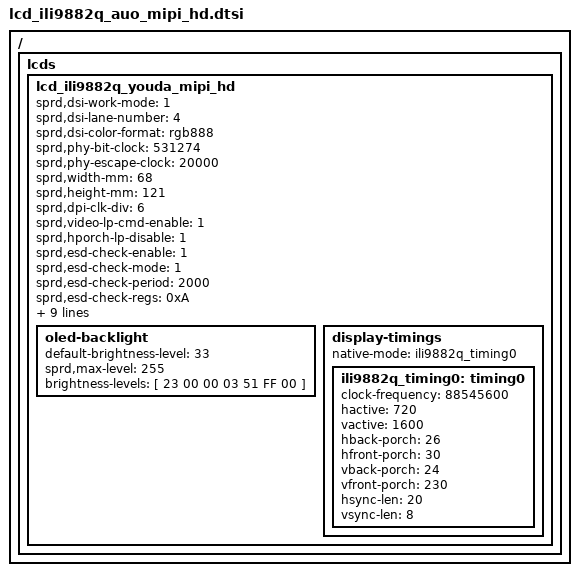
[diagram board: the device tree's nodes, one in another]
/ {
	fragment {
		target-path = "/";
		__overlay__ {
			lcds {
				lcd_ili9882q_youda_mipi_hd: lcd_ili9882q_youda_mipi_hd {

				sprd,dsi-work-mode = <1>; /* video burst mode*/
				sprd,dsi-lane-number = <4>;
				sprd,dsi-color-format = "rgb888";

				sprd,phy-bit-clock = <531274>;	/* kbps */
				sprd,phy-escape-clock = <20000>;/* kHz */
				sprd,width-mm = <68>;
				sprd,height-mm = <121>;
				sprd,dpi-clk-div = <6>;
				sprd,video-lp-cmd-enable = <1>;
				sprd,hporch-lp-disable = <1>;

				sprd,esd-check-enable = <1>;
				sprd,esd-check-mode = <1>;
				sprd,esd-check-period = <2000>;
				sprd,esd-check-regs = <0xA>;
				sprd,esd-return-code = <0x9C>;

				sprd,reset-on-sequence = <1 5>, <0 5>, <1 20>;
				sprd,reset-off-sequence = <1 5>;

				sprd,initial-command = [
					39 00 00 04 FF 98 82 06
					23 00 00 02 3E 60
					39 00 00 04 FF 98 82 01
					23 00 00 02 00 4C
					23 00 00 02 01 25
					23 00 00 02 02 00
					23 00 00 02 03 00
					23 00 00 02 04 03
					23 00 00 02 05 25
					23 00 00 02 06 00
					23 00 00 02 07 00
					23 00 00 02 08 84
					23 00 00 02 09 85
					23 00 00 02 0A F5
					23 00 00 02 0B 00
					23 00 00 02 0C 07
					23 00 00 02 0D 07
					23 00 00 02 0E 00
					23 00 00 02 0F 00
					23 00 00 02 10 00
					23 00 00 02 11 00
					23 00 00 02 12 00
					23 00 00 02 14 87
					23 00 00 02 15 87
					23 00 00 02 16 84
					23 00 00 02 17 85
					23 00 00 02 18 75
					23 00 00 02 19 00
					23 00 00 02 1A 06
					23 00 00 02 1B 06
					23 00 00 02 1C 00
					23 00 00 02 1D 00
					23 00 00 02 1E 00
					23 00 00 02 1F 00
					23 00 00 02 20 00
					23 00 00 02 22 87
					23 00 00 02 23 87
					23 00 00 02 2A 8B
					23 00 00 02 2B 4E
					23 00 00 02 31 2A
					23 00 00 02 32 2A
					23 00 00 02 33 0C
					23 00 00 02 34 0C
					23 00 00 02 35 23
					23 00 00 02 36 23
					23 00 00 02 37 2A
					23 00 00 02 38 2A
					23 00 00 02 39 10
					23 00 00 02 3A 07
					23 00 00 02 3B 18
					23 00 00 02 3C 12
					23 00 00 02 3D 1A
					23 00 00 02 3E 14
					23 00 00 02 3F 1C
					23 00 00 02 40 16
					23 00 00 02 41 1E
					23 00 00 02 42 08
					23 00 00 02 43 08
					23 00 00 02 44 2A
					23 00 00 02 45 2A
					23 00 00 02 46 2A
					23 00 00 02 47 2A
					23 00 00 02 48 2A
					23 00 00 02 49 0D
					23 00 00 02 4A 0D
					23 00 00 02 4B 23
					23 00 00 02 4C 23
					23 00 00 02 4D 2A
					23 00 00 02 4E 2A
					23 00 00 02 4F 11
					23 00 00 02 50 07
					23 00 00 02 51 19
					23 00 00 02 52 13
					23 00 00 02 53 1B
					23 00 00 02 54 15
					23 00 00 02 55 1D
					23 00 00 02 56 17
					23 00 00 02 57 1F
					23 00 00 02 58 09
					23 00 00 02 59 09
					23 00 00 02 5A 2A
					23 00 00 02 5B 2A
					23 00 00 02 5C 2A
					23 00 00 02 61 2A
					23 00 00 02 62 2A
					23 00 00 02 63 09
					23 00 00 02 64 09
					23 00 00 02 65 2A
					23 00 00 02 66 2A
					23 00 00 02 67 23
					23 00 00 02 68 23
					23 00 00 02 69 1F
					23 00 00 02 6A 07
					23 00 00 02 6B 17
					23 00 00 02 6C 1D
					23 00 00 02 6D 15
					23 00 00 02 6E 1B
					23 00 00 02 6F 13
					23 00 00 02 70 19
					23 00 00 02 71 11
					23 00 00 02 72 0D
					23 00 00 02 73 0D
					23 00 00 02 74 2A
					23 00 00 02 75 2A
					23 00 00 02 76 2A
					23 00 00 02 77 2A
					23 00 00 02 78 2A
					23 00 00 02 79 08
					23 00 00 02 7A 08
					23 00 00 02 7B 2A
					23 00 00 02 7C 2A
					23 00 00 02 7D 23
					23 00 00 02 7E 23
					23 00 00 02 7F 1E
					23 00 00 02 80 07
					23 00 00 02 81 16
					23 00 00 02 82 1C
					23 00 00 02 83 14
					23 00 00 02 84 1A
					23 00 00 02 85 12
					23 00 00 02 86 18
					23 00 00 02 87 10
					23 00 00 02 88 0C
					23 00 00 02 89 0C
					23 00 00 02 8A 2A
					23 00 00 02 8B 2A
					23 00 00 02 8C 2A
					23 00 00 02 B9 10
					23 00 00 02 C3 00
					23 00 00 02 C4 80
					23 00 00 02 D3 20
					23 00 00 02 D5 05
					23 00 00 02 D6 20
					23 00 00 02 DD 20
					39 00 00 04 FF 98 82 02
					23 00 00 02 F1 1C
					23 00 00 02 4B 5A
					23 00 00 02 50 CA
					23 00 00 02 51 00
					23 00 00 02 06 8E
					23 00 00 02 0B A0
					23 00 00 02 0C 00
					23 00 00 02 0D 20
					23 00 00 02 0E E6
					23 00 00 02 4E 11
					23 00 00 02 4D CE
					23 00 00 02 F2 4A
					39 00 00 04 FF 98 82 05
					23 00 00 02 03 00
					23 00 00 02 04 CB
					23 00 00 02 58 61
					23 00 00 02 63 88
					23 00 00 02 64 88
					23 00 00 02 68 A1
					23 00 00 02 69 A7
					23 00 00 02 6A 79
					23 00 00 02 6B 6B
					23 00 00 02 85 37
					39 00 00 04 FF 98 82 06
					23 00 00 02 D9 1F
					23 00 00 02 C0 40
					23 00 00 02 C1 16
					23 00 00 02 80 08
					39 00 00 04 FF 98 82 08
					39 00 00 1C E0 00 27 7C B4 F1 55 22 49 75 97 A5 CD F8 1E 43 AA 6A 99 B9 E0 FF 03 30 67 79 03 8A
					39 00 00 1C E1 00 27 7C B4 F1 55 22 49 75 97 A5 CD F8 1E 43 AA 6A 99 B9 E0 FF 03 30 67 79 03 8A
					39 00 00 04 FF 98 82 0B
					23 00 00 02 9A 44
					23 00 00 02 9B 78
					23 00 00 02 9C 03
					23 00 00 02 9D 03
					23 00 00 02 9E 70
					23 00 00 02 9F 70
					23 00 00 02 AB E0
					23 00 00 02 AC 7F
					23 00 00 02 AD 3F
					39 00 00 04 FF 98 82 0E
					23 00 00 02 11 10
					23 00 00 02 12 08
					23 00 00 02 13 10
					23 00 00 02 00 A0

					39 00 00 04 FF 98 82 03
					39 00 00 02 83 E0  //DBV[15..9] 8bit
					39 00 00 02 84 07  //PWM=15.6K

					39 00 00 04 FF 98 82 00
					39 00 00 03 51 FF 00
					23 00 00 02 53 2C
					23 00 00 02 55 01
					23 00 00 02 35 00
					23 78 00 02 11 00
					23 14 00 02 29 00
				];

				sprd,sleep-in-command = [
					13 14 00 01 28
					13 78 00 01 10
				];

				sprd,sleep-out-command = [
					13 78 00 01 11
					13 14 00 01 29
				];

				oled-backlight {
						default-brightness-level = <33>;
						sprd,max-level = <255>;

						brightness-levels = [
							23 00 00 03 51 FF 00
							];
						};
				display-timings {
					native-mode = <&ili9882q_timing0>;
					ili9882q_timing0: timing0 {
							clock-frequency = <88545600>;
							hactive = <720>;
							vactive = <1600>;
							hback-porch = <26>;
							hfront-porch = <30>;
							vback-porch = <24>;
							vfront-porch = <230>;
							hsync-len = <20>;
							vsync-len = <8>;
						};
					};
				};
			};
		};
	};
};
